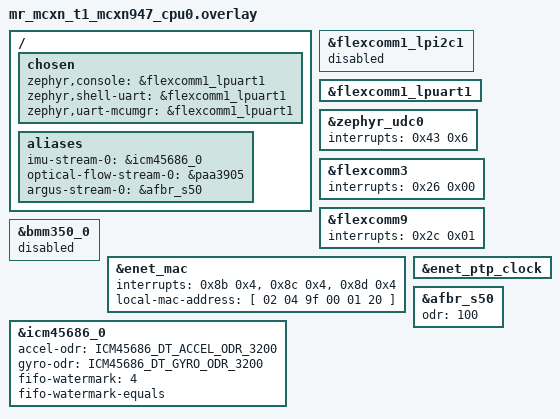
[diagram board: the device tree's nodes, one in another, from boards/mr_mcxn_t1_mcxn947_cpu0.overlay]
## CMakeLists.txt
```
#-------------------------------------------------------------------------------
# Zephyr Spinali Application
#
# Copyright (c) 2023 CogniPilot Foundation
# SPDX-License-Identifier: Apache-2.0

cmake_minimum_required(VERSION 3.13.1)

set(SPINALI_SYNAPSE_FBS_ROOT "" CACHE PATH "Generated Synapse C package")
if(NOT SPINALI_SYNAPSE_FBS_ROOT AND DEFINED ENV{SPINALI_SYNAPSE_FBS_ROOT})
  set(SPINALI_SYNAPSE_FBS_ROOT "$ENV{SPINALI_SYNAPSE_FBS_ROOT}" CACHE PATH
    "Generated Synapse C package" FORCE)
endif()
if(SPINALI_SYNAPSE_FBS_ROOT)
  list(APPEND ZEPHYR_EXTRA_MODULES ${SPINALI_SYNAPSE_FBS_ROOT})
endif()

find_package(Zephyr REQUIRED HINTS $ENV{ZEPHYR_BASE})

project(optical_flow LANGUAGES C)

# Validate HCDF SHA at build time
if(DEFINED ZEPHYR_HCDF_MODELS_MODULE_DIR)
  include(${ZEPHYR_HCDF_MODELS_MODULE_DIR}/cmake/hcdf.cmake)
  hcdf_validate_sha(BOARD mr_mcxn_t1 DEVICE optical-flow)
endif()

set(flags
  -std=c11
  -Wall
  -Wextra
  -Werror
  -Wstrict-prototypes
  -Waggregate-return
  -Wbad-function-cast
  -Wcast-align
  -Wcast-qual
  -Wfloat-equal
  -Wformat-security
  -Wlogical-op
  -Wmissing-declarations
  -Wmissing-include-dirs
  -Wmissing-prototypes
  -Wnested-externs
  -Wpointer-arith
  -Wredundant-decls
  -Wsequence-point
  -Wshadow
  -Wstrict-prototypes
  -Wswitch
  -Wundef
  -Wunreachable-code
  -Wunused-but-set-parameter
  -Wwrite-strings
  )
string(JOIN " " flags ${flags})

set(SOURCE_FILES
  src/boot_banner.c
  )

set_source_files_properties(
  ${SOURCE_FILES}
  PROPERTIES COMPILE_FLAGS
  "${flags}"
  )

target_sources(app PRIVATE ${SOURCE_FILES})

if(CONFIG_SPINALI_SYNAPSE_WIRE)
  if(NOT TARGET synapse_fbs::wire)
    message(FATAL_ERROR
      "SPINALI_SYNAPSE_FBS_ROOT must provide synapse_fbs::wire. "
      "Generate the package with scripts/synapse_fbs_package and set "
      "SPINALI_SYNAPSE_FBS_ROOT to its printed path."
    )
  endif()
  target_link_libraries(app PRIVATE synapse_fbs::wire)
endif()

if(CONFIG_SPINALI_SYNAPSE_ROS_CDR)
  if(NOT TARGET synapse_fbs::cdr)
    message(FATAL_ERROR
      "SPINALI_SYNAPSE_FBS_ROOT must provide synapse_fbs::cdr. "
      "Generate the package with scripts/synapse_fbs_package and set "
      "SPINALI_SYNAPSE_FBS_ROOT to its printed path."
    )
  endif()
  target_link_libraries(app PRIVATE synapse_fbs::cdr)
endif()

target_include_directories(app SYSTEM BEFORE PRIVATE ${ZEPHYR_BASE}/include ${CMAKE_BINARY_DIR})

# vi: ts=2 sw=2 et
```

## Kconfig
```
# Copyright (c) 2023, CogniPilot Foundation
# SPDX-License-Identifier: Apache-2.0

mainmenu "CogniPilot - SPINALI - OPTICAL FLOW"
menu "Zephyr"
source "Kconfig.zephyr"
endmenu

menu "OPTICAL_FLOW"

config SPINALI_OPTICAL_FLOW_LIGHTING
  bool "enable lighting"
  help
    Enable lighting

module = SPINALI_OPTICAL_FLOW
module-str = spinali_optical_flow
source "subsys/logging/Kconfig.template.log_config"
endmenu
```

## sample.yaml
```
sample:
  description: optical_flow
  name: optical_flow
common:
  build_only: true
tests:
  optical_flow.mr_mcxn_t1/mcxn947/cpu0:
    tags:
      - optical_flow
    integration_platforms:
      - mr_mcxn_t1/mcxn947/cpu0
```

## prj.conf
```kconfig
CONFIG_SPINALI=y
CONFIG_SPINALI_APP_NAME="Optical Flow"

# CONFIG_BOOTLOADER_MCUBOOT=y
# CONFIG_MCUBOOT_SIGNATURE_KEY_FILE="../../../bootloader/mcuboot/root-rsa-2048.pem"
CONFIG_ZCBOR=y
CONFIG_MCUMGR=y
CONFIG_MCUMGR_TRANSPORT_UDP=y
CONFIG_MCUMGR_TRANSPORT_UDP_IPV6=y
CONFIG_MCUMGR_GRP_OS=y
CONFIG_MCUMGR_GRP_OS_INFO=y
CONFIG_MCUMGR_GRP_OS_INFO_BUILD_DATE_TIME=y
CONFIG_MCUMGR_GRP_OS_INFO_CUSTOM_HOOKS=y
CONFIG_MCUMGR_MGMT_NOTIFICATION_HOOKS=y
CONFIG_HWINFO=y
CONFIG_MCUMGR_GRP_OS_BOOTLOADER_INFO=y
CONFIG_MCUMGR_GRP_OS_MCUMGR_PARAMS=y
CONFIG_THREAD_MONITOR=y
CONFIG_THREAD_NAME=y
CONFIG_MCUMGR_GRP_OS_TASKSTAT=y
CONFIG_MCUMGR_GRP_OS_TASKSTAT_USE_THREAD_NAME_FOR_NAME=y
CONFIG_THREAD_STACK_INFO=y
CONFIG_FLASH=y
CONFIG_FLASH_MAP=y
CONFIG_IMG_MANAGER=y
CONFIG_STREAM_FLASH=y
CONFIG_MCUMGR_GRP_IMG=y
CONFIG_MCUMGR_GRP_IMG_SLOT_INFO=y
CONFIG_SHELL_BACKEND_DUMMY=y
CONFIG_BASE64=y
CONFIG_MCUMGR_GRP_SHELL=y
CONFIG_STATS=y
CONFIG_STATS_NAMES=y
CONFIG_MCUMGR_GRP_STAT=y
CONFIG_SYS_CLOCK_TICKS_PER_SEC=10000
CONFIG_TICKLESS_KERNEL=n
CONFIG_I3C=n
CONFIG_TEST_RANDOM_GENERATOR=y
CONFIG_FPU=y

CONFIG_NET_BUF_RX_COUNT=36
CONFIG_NET_PKT_RX_COUNT=36
CONFIG_NET_BUF_TX_COUNT=36
CONFIG_NET_PKT_TX_COUNT=24

CONFIG_ZROS_SENSE_STREAM=y
CONFIG_ZROS_SENSE_STREAM_IMU=y
CONFIG_ZROS_SENSE_STREAM_MAG=n
CONFIG_ZROS_SENSE_STREAM_OPTICAL_FLOW=y
CONFIG_ZROS_SENSE_STREAM_ARGUS_POINTCLOUD=y
CONFIG_ZROS_SENSE_STREAM_ARGUS=y

CONFIG_SHELL=y
CONFIG_SENSOR=y
CONFIG_SENSOR_SHELL=y
CONFIG_SENSOR_INFO=y

CONFIG_SPINALI_SYNAPSE_MCUMGR_HOOKS=y
CONFIG_MCUMGR_GRP_HCDF=y
CONFIG_MCUMGR_GRP_HCDF_URL="https://hcdf.cognipilot.org/mr_mcxn_t1/optical-flow/optical-flow.hcdf"
CONFIG_MCUMGR_GRP_HCDF_SHA="d9507e38"

CONFIG_SPINALI_SYNAPSE_TOPIC=y
CONFIG_SPINALI_CORE_COMMON=y
CONFIG_SPINALI_CORE_COMMON_BOOT_BANNER=y
CONFIG_ZROS=y
CONFIG_SHELL_STACK_SIZE=8192
CONFIG_INIT_STACKS=y

CONFIG_LOG=y
CONFIG_LOG_CMDS=y
CONFIG_LOG_MODE_DEFERRED=y

CONFIG_SPINALI_OPTICAL_FLOW_LOG_LEVEL_DBG=y

CONFIG_SENSOR_SHELL_THREAD_STACK_SIZE=8192
CONFIG_SENSOR_LOG_LEVEL_DBG=n

# modules

# General config
CONFIG_MAIN_THREAD_PRIORITY=5
CONFIG_SYSTEM_WORKQUEUE_PRIORITY=-2

# Networking config
CONFIG_NET_SHELL=y
CONFIG_NETWORKING=y
CONFIG_NET_IPV4=n
CONFIG_NET_IPV6=y
# IPv6-native, router-less peer mesh, no IPv4. IPv6 multicast (MLD) joins the
# ff02:: mesh group, and a stable EUI-64 interface identifier from the role MAC
# makes the mesh address zero-config and reboot-stable. MCUmgr rides IPv6 UDP.
CONFIG_NET_IPV6_MLD=y
CONFIG_NET_IPV6_IID_EUI_64=y
CONFIG_NET_UDP=y
CONFIG_NET_TCP=y
CONFIG_NET_SOCKETS=y
CONFIG_NET_VLAN=y
CONFIG_NET_VLAN_COUNT=1
CONFIG_NET_IF_MAX_IPV6_COUNT=2
CONFIG_NET_CONTEXT_PRIORITY=y

# gPTP (IEEE 802.1AS) SLAVE clock over the T1 link.
# This node runs the gPTP stack without GrandMaster capability (priority1 255),
# so it always yields to the coe grandmaster and follows it as a slave. The
# Ethernet MAC PTP hardware clock (PHC) is then steered onto the grandmaster's
# GNSS-traceable timescale, and the optical-flow producer reads it once synced
# so its timestamps share that domain. NET_GPTP selects PTP_CLOCK and the
# network packet timestamping path (NET_L2_PTP_TIMESTAMPING); PTP_CLOCK is
# listed explicitly to keep the ENET QoS PHC in the build if that select ever
# changes. No GNSS/PPS discipline (SPINALI_TIMING) runs here: the shared time
# arrives over gPTP from the grandmaster, not from a local receiver.
CONFIG_NET_GPTP=y
CONFIG_PTP_CLOCK=y
# Static timeReceiver: the port is pinned to the slave role and the PHC is
# disciplined from received Sync/Follow_Up alone, so the node also locks
# behind an automotive-profile bridge that sends no Announce.
CONFIG_NET_GPTP_STATIC_TIME_RECEIVER=y

# Network address config
CONFIG_NET_HOSTNAME="optical-flow"
CONFIG_NET_CONFIG_SETTINGS=y
CONFIG_NET_STATISTICS=y
CONFIG_NET_MGMT_EVENT_INFO=y
CONFIG_NET_MGMT_EVENT_MONITOR=y
CONFIG_NET_BUF_POOL_USAGE=y
CONFIG_NET_DEBUG_NET_PKT_ALLOC=y
CONFIG_NET_CONFIG_NEED_IPV4=n
CONFIG_NET_CONFIG_MY_IPV6_ADDR=""
CONFIG_NET_CONFIG_INIT_TIMEOUT=0

# STATS
CONFIG_THREAD_RUNTIME_STATS=y
CONFIG_SCHED_THREAD_USAGE=y
CONFIG_SCHED_THREAD_USAGE_ANALYSIS=y
CONFIG_SCHED_THREAD_USAGE_ALL=y
CONFIG_SCHED_THREAD_USAGE_AUTO_ENABLE=y

CONFIG_SPEED_OPTIMIZATIONS=y
CONFIG_ZVFS_OPEN_MAX=16
CONFIG_HEAP_MEM_POOL_SIZE=49152

# Vehicle Optical Flow processing: PAA3905 flow + AFBR range fused into the
# synapse OpticalFlow / OpticalFlowVelocity topics the bridge carries. VOF_RATE=0
# runs the processing at the sensor's motion-driven ODR (up to the 126 Hz PAA3905
# frame rate) with no cap, so no flow frame is dropped before it reaches the mesh.
CONFIG_SPINALI_VEHICLE_OPTICAL_FLOW=y
CONFIG_VOF_RATE=0

# Direct delivery to TROPIC of OpticalFlowVelocity on 46010 and of the raw
# OpticalFlowData on 46011, which the vehicle's tightly coupled flow path
# fuses. This is independent of the optional ROS 2 CDR mirror and does not
# require Zenoh.
CONFIG_SPINALI_SYNAPSE_WIRE=y
CONFIG_SPINALI_SYNAPSE_WIRE_TOPIC_OPTICAL_FLOW=y
CONFIG_SPINALI_SYNAPSE_WIRE_TOPIC_OPTICAL_FLOW_RAW=y
CONFIG_SPINALI_SYNAPSE_WIRE_OPTICAL_FLOW_RAW_PORT=46011
CONFIG_SPINALI_SYNAPSE_WIRE_DESTINATION="fe80::4:9fff:fe00:150"
CONFIG_SPINALI_SYNAPSE_WIRE_DESTINATION_MAC="02:04:9f:00:01:50"
CONFIG_SPINALI_SYNAPSE_WIRE_SOURCE_NODE_ID=12
CONFIG_SPINALI_SYNAPSE_WIRE_RATE_HZ=70
CONFIG_SPINALI_SYNAPSE_WIRE_PCP=5
CONFIG_SPINALI_SYNAPSE_WIRE_LOG_LEVEL_INF=y

# Optional ROS 2 mirror. This publishes the same optical sample at 20 Hz as
# exact CDRv1 through the local rmw_zenoh router. It is not on the estimator
# path and does not affect direct-wire delivery.
CONFIG_SYNAPSE_FBS_CDR=y
CONFIG_SPINALI_SYNAPSE_ROS_CDR=y
CONFIG_SPINALI_SYNAPSE_ROS_CDR_TOPIC_OPTICAL_FLOW=y
CONFIG_SPINALI_SYNAPSE_ROS_CDR_RATE_HZ=20
CONFIG_SPINALI_SYNAPSE_ROS_CDR_ROUTER="udp/[fe80::f22f:74ff:fecc:4a66]:7447#iface=vlan0"
CONFIG_SPINALI_SYNAPSE_ROS_CDR_ROUTER_ADDRESS="fe80::f22f:74ff:fecc:4a66"
CONFIG_SPINALI_SYNAPSE_ROS_CDR_ROUTER_MAC="f0:2f:74:cc:4a:66"
CONFIG_SPINALI_SYNAPSE_ROS_CDR_LOG_LEVEL_INF=y

CONFIG_ZENOH_PICO=y
CONFIG_ZENOH_PICO_UNSTABLE_API=y
CONFIG_ZENOH_PICO_MULTI_THREAD=y
CONFIG_ZENOH_PICO_PUBLICATION=y
CONFIG_ZENOH_PICO_LINK_UDP_UNICAST=y
CONFIG_ZENOH_PICO_LINK_UDP_MULTICAST=n
CONFIG_ZENOH_PICO_SCOUTING=n
CONFIG_ZENOH_PICO_ZEPHYR_THREADS_NATIVE=y
CONFIG_ZENOH_PICO_ZEPHYR_TASK_POOL_SIZE=4
CONFIG_ZENOH_PICO_ZEPHYR_TASK_STACK_SIZE=4096
CONFIG_ZENOH_PICO_ZEPHYR_TASK_PRIORITY_CUSTOM=y
CONFIG_ZENOH_PICO_ZEPHYR_TASK_PRIORITY=7
CONFIG_ZENOH_PICO_ZEPHYR_SOCKET_PRIORITY=y
CONFIG_ZENOH_PICO_ZEPHYR_UNICAST_PRIORITY=5
```

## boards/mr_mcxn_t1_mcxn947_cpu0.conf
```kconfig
CONFIG_ICM45686_STREAM=y
CONFIG_PAA3905_STREAM=y
CONFIG_BMM350_STREAM=y
CONFIG_RTIO_WORKQ_THREADS_POOL_PRIO=4
CONFIG_I2C_RTIO_SQ_SIZE=8
CONFIG_I2C_RTIO_CQ_SIZE=8

CONFIG_DEBUG=y
CONFIG_CPU_LOAD=y
CONFIG_CPU_LOAD_LOG_PERIODICALLY=5000
```

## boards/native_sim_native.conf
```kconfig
CONFIG_BOOTLOADER_MCUBOOT=n
CONFIG_SPINALI_SENSE_IMU=n
CONFIG_HEAP_MEM_POOL_SIZE=262144
CONFIG_DEBUG_OPTIMIZATIONS=y
CONFIG_NET_TCP=y
CONFIG_MAX_PTHREAD_MUTEX_COUNT=10
CONFIG_MAX_PTHREAD_COND_COUNT=10
```

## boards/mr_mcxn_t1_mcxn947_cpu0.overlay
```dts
/* SPDX-License-Identifier: Apache-2.0 */
/* Copyright 2025 CogniPilot Foundation */

/ {
	chosen {
		zephyr,console = &flexcomm1_lpuart1;
		zephyr,shell-uart = &flexcomm1_lpuart1;
		zephyr,uart-mcumgr = &flexcomm1_lpuart1;
	};

	aliases {
		imu-stream-0 = &icm45686_0;
		optical-flow-stream-0 = &paa3905;
		argus-stream-0 = &afbr_s50;
	};
};

&flexcomm1_lpi2c1 {
	status = "disabled";
};

&flexcomm1_lpuart1 {
	status = "okay";
};

/* USB Shell IRQ priority lower than SPI IRQs */
&zephyr_udc0 {
	interrupts = <0x43 0x6>;
};

/* AFBR-S50 SPI priority */
&flexcomm3 {
	interrupts = <0x26 0x00>;
};

/* PAA3905 SPI priority */
&flexcomm9 {
	interrupts = <0x2c 0x01>;
};

/* Disable unused sensors */
&bmm350_0 {
	status = "disabled";
};

/* icm45686_1 not aliased - not used for streaming */

/* Lower ethernet MAC interrupt priority to prevent early RX before net stack
 * ready. Also pins the role-derived interface identity for node 12
 * (optical_flow): a locally administered MAC whose final 12 bits read as the
 * decimal node id followed by a zero in hex, so node 12 is 02:04:9f:00:01:20.
 * The EUI-64 IPv6 link-local address follows from it as fe80::4:9fff:fe00:120.
 * The role MAC replaces the silicon-derived nxp,unique-mac from the board dtsi
 * (the enet-qos driver honors local-mac-address only when nxp,unique-mac is
 * absent), so the firmware image is identical across hardware sets. The gPTP
 * clock identity is derived from this MAC, which is intended.
 */
&enet_mac {
	interrupts = <0x8b 0x4>, <0x8c 0x4>, <0x8d 0x4>;
	/delete-property/ nxp,unique-mac;
	local-mac-address = [ 02 04 9f 00 01 20 ];
};

/* ENET QoS PTP hardware clock (PHC): disabled by default in the SoC dtsi.
 * Enabled here so the gPTP slave stack has a clock to discipline and the
 * optical-flow producer can read it. Steered to follow the coe grandmaster
 * over the T1 link, it puts the published timestamps on the shared,
 * GNSS-traceable timescale once this node acquires sync.
 */
&enet_ptp_clock {
	status = "okay";
};

#include <zephyr/dt-bindings/sensor/icm45686.h>

&icm45686_0 {
	/* Configure to output 4-samples every 1.25-ms (800-Hz) */
	accel-odr = <ICM45686_DT_ACCEL_ODR_3200>;
	gyro-odr = <ICM45686_DT_GYRO_ODR_3200>;
	fifo-watermark = <4>;
	fifo-watermark-equals;
};

&afbr_s50 {
	odr = <100>;
};
```

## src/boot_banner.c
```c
/*
 * Copyright (c) 2023 CogniPilot Foundation
 * SPDX-License-Identifier: Apache-2.0
 */

#include <zephyr/kernel.h>
#include <zephyr/logging/log.h>

#if defined(CONFIG_SPINALI_CORE_COMMON_BOOT_BANNER)
#include <stdio.h>
#endif

#include <spinali/core/common.h>

LOG_MODULE_REGISTER(optical_flow_boot_banner, CONFIG_SPINALI_OPTICAL_FLOW_LOG_LEVEL);

static int optical_flow_boot_banner_sys_init(void)
{
	LOG_INF("Spinali Optical Flow %d.%d.%d", CONFIG_SPINALI_VERSION_MAJOR,
		CONFIG_SPINALI_VERSION_MINOR, CONFIG_SPINALI_VERSION_PATCH);
#if defined(CONFIG_SPINALI_CORE_COMMON_BOOT_BANNER)
	printf("%s", banner_spinali);
#endif
	return 0;
};

SYS_INIT(optical_flow_boot_banner_sys_init, APPLICATION, 0);

// vi: ts=4 sw=4 et
```
